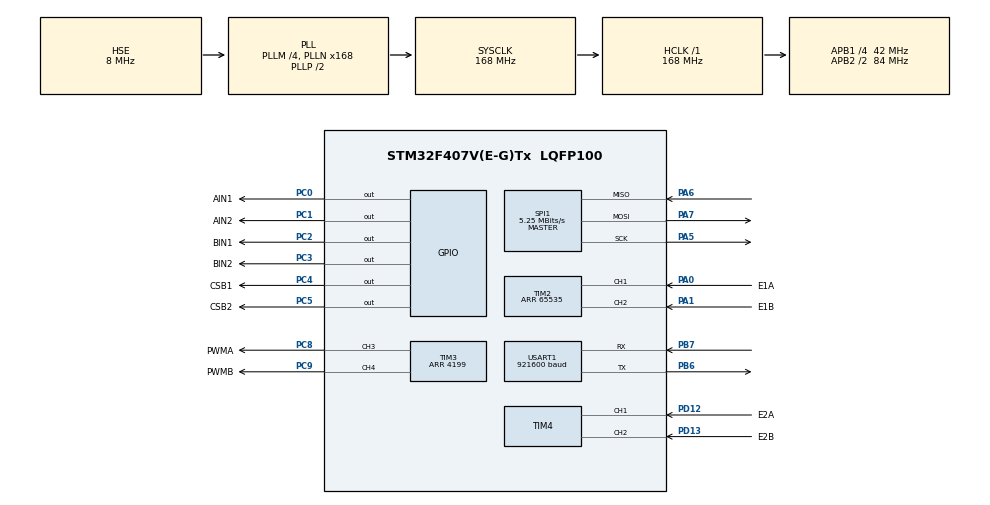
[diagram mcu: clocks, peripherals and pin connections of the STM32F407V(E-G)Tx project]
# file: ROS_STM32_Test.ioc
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Dma.Request0=SPI1_RX
Dma.Request1=SPI1_TX
Dma.Request2=USART1_RX
Dma.Request3=USART1_TX
Dma.SPI1_RX.0.Direction=DMA_PERIPH_TO_MEMORY
Dma.SPI1_RX.0.FIFOMode=DMA_FIFOMODE_DISABLE
Dma.SPI1_RX.0.Instance=DMA2_Stream0
Dma.SPI1_RX.0.MemDataAlignment=DMA_MDATAALIGN_BYTE
Dma.SPI1_RX.0.MemInc=DMA_MINC_ENABLE
Dma.SPI1_RX.0.Mode=DMA_NORMAL
Dma.SPI1_RX.0.PeriphDataAlignment=DMA_PDATAALIGN_BYTE
Dma.SPI1_RX.0.PeriphInc=DMA_PINC_DISABLE
Dma.SPI1_RX.0.Priority=DMA_PRIORITY_VERY_HIGH
Dma.SPI1_TX.1.Direction=DMA_MEMORY_TO_PERIPH
Dma.SPI1_TX.1.FIFOMode=DMA_FIFOMODE_DISABLE
Dma.SPI1_TX.1.Instance=DMA2_Stream3
Dma.SPI1_TX.1.MemDataAlignment=DMA_MDATAALIGN_BYTE
Dma.SPI1_TX.1.MemInc=DMA_MINC_ENABLE
Dma.SPI1_TX.1.Mode=DMA_NORMAL
Dma.SPI1_TX.1.PeriphDataAlignment=DMA_PDATAALIGN_BYTE
Dma.SPI1_TX.1.PeriphInc=DMA_PINC_DISABLE
Dma.SPI1_TX.1.Priority=DMA_PRIORITY_VERY_HIGH
Dma.USART1_RX.2.Direction=DMA_PERIPH_TO_MEMORY
Dma.USART1_RX.2.FIFOMode=DMA_FIFOMODE_DISABLE
Dma.USART1_RX.2.Instance=DMA2_Stream2
Dma.USART1_RX.2.MemDataAlignment=DMA_MDATAALIGN_BYTE
Dma.USART1_RX.2.MemInc=DMA_MINC_ENABLE
Dma.USART1_RX.2.Mode=DMA_CIRCULAR
Dma.USART1_RX.2.PeriphDataAlignment=DMA_PDATAALIGN_BYTE
Dma.USART1_RX.2.PeriphInc=DMA_PINC_DISABLE
Dma.USART1_RX.2.Priority=DMA_PRIORITY_HIGH
Dma.USART1_TX.3.Direction=DMA_MEMORY_TO_PERIPH
Dma.USART1_TX.3.FIFOMode=DMA_FIFOMODE_DISABLE
Dma.USART1_TX.3.Instance=DMA2_Stream7
Dma.USART1_TX.3.MemDataAlignment=DMA_MDATAALIGN_BYTE
Dma.USART1_TX.3.MemInc=DMA_MINC_ENABLE
Dma.USART1_TX.3.Mode=DMA_NORMAL
Dma.USART1_TX.3.PeriphDataAlignment=DMA_PDATAALIGN_BYTE
Dma.USART1_TX.3.PeriphInc=DMA_PINC_DISABLE
Dma.USART1_TX.3.Priority=DMA_PRIORITY_HIGH
Mcu.Family=STM32F4
Mcu.Name=STM32F407V(E-G)Tx
Mcu.Package=LQFP100
NVIC.DMA2_Stream0_IRQn=true\:0\:0\:false\:false\:true\:false\:true\:true
NVIC.DMA2_Stream2_IRQn=true\:0\:0\:false\:false\:true\:false\:true\:true
NVIC.DMA2_Stream3_IRQn=true\:0\:0\:false\:false\:true\:false\:true\:true
NVIC.DMA2_Stream7_IRQn=true\:0\:0\:false\:false\:true\:false\:true\:true
NVIC.PriorityGroup=NVIC_PRIORITYGROUP_4
NVIC.SPI1_IRQn=true\:0\:0\:false\:false\:true\:true\:true\:true
NVIC.TIM8_BRK_TIM12_IRQn=true\:2\:0\:true\:false\:true\:true\:true\:true
NVIC.USART1_IRQn=true\:1\:0\:true\:false\:true\:false\:true\:true
PA0-WKUP.GPIO_Label=E1A
PA0-WKUP.Signal=S_TIM2_CH1_ETR
PA1.GPIO_Label=E1B
PA1.Signal=S_TIM2_CH2
PA5.Mode=Full_Duplex_Master
PA5.Signal=SPI1_SCK
PA6.Mode=Full_Duplex_Master
PA6.Signal=SPI1_MISO
PA7.Mode=Full_Duplex_Master
PA7.Signal=SPI1_MOSI
PB6.Mode=Asynchronous
PB6.Signal=USART1_TX
PB7.Mode=Asynchronous
PB7.Signal=USART1_RX
PC0.GPIO_Label=AIN1
PC0.GPIO_Speed=GPIO_SPEED_FREQ_VERY_HIGH
PC0.PinState=GPIO_PIN_RESET
PC0.Signal=GPIO_Output
PC1.GPIO_Label=AIN2
PC1.GPIO_Speed=GPIO_SPEED_FREQ_VERY_HIGH
PC1.PinState=GPIO_PIN_RESET
PC1.Signal=GPIO_Output
PC2.GPIO_Label=BIN1
PC2.GPIO_Speed=GPIO_SPEED_FREQ_VERY_HIGH
PC2.PinState=GPIO_PIN_RESET
PC2.Signal=GPIO_Output
PC3.GPIO_Label=BIN2
PC3.GPIO_Speed=GPIO_SPEED_FREQ_VERY_HIGH
PC3.PinState=GPIO_PIN_RESET
PC3.Signal=GPIO_Output
PC4.GPIO_Label=CSB1
PC4.GPIO_Speed=GPIO_SPEED_FREQ_VERY_HIGH
PC4.PinState=GPIO_PIN_SET
PC4.Signal=GPIO_Output
PC5.GPIO_Label=CSB2
PC5.GPIO_Speed=GPIO_SPEED_FREQ_VERY_HIGH
PC5.PinState=GPIO_PIN_SET
PC5.Signal=GPIO_Output
PC8.GPIO_Label=PWMA
PC8.Signal=S_TIM3_CH3
PC9.GPIO_Label=PWMB
PC9.Signal=S_TIM3_CH4
PD12.GPIO_Label=E2A
PD12.Signal=S_TIM4_CH1
PD13.GPIO_Label=E2B
PD13.Signal=S_TIM4_CH2
PH0-OSC_IN.Mode=HSE-External-Oscillator
PH0-OSC_IN.Signal=RCC_OSC_IN
PH1-OSC_OUT.Mode=HSE-External-Oscillator
PH1-OSC_OUT.Signal=RCC_OSC_OUT
ProjectManager.HeapSize=0x200
ProjectManager.StackSize=0x400
ProjectManager.TargetToolchain=MDK-ARM V5.32
RCC.48MHZClocksFreq_Value=84000000
RCC.AHBFreq_Value=168000000
RCC.APB1CLKDivider=RCC_HCLK_DIV4
RCC.APB1Freq_Value=42000000
RCC.APB1TimFreq_Value=84000000
RCC.APB2CLKDivider=RCC_HCLK_DIV2
RCC.APB2Freq_Value=84000000
RCC.APB2TimFreq_Value=168000000
RCC.CortexFreq_Value=168000000
RCC.HCLKFreq_Value=168000000
RCC.HSE_VALUE=8000000
RCC.HSI_VALUE=16000000
RCC.LSE_VALUE=32768
RCC.PLLM=4
RCC.PLLN=168
RCC.PLLSourceVirtual=RCC_PLLSOURCE_HSE
RCC.SYSCLKFreq_VALUE=168000000
RCC.SYSCLKSource=RCC_SYSCLKSOURCE_PLLCLK
RCC.VCOOutputFreq_Value=336000000
SH.S_TIM2_CH1_ETR.0=TIM2_CH1,Encoder_Interface
SH.S_TIM2_CH2.0=TIM2_CH2,Encoder_Interface
SH.S_TIM3_CH3.0=TIM3_CH3,PWM Generation3 CH3
SH.S_TIM3_CH4.0=TIM3_CH4,PWM Generation4 CH4
SH.S_TIM4_CH1.0=TIM4_CH1,Encoder_Interface
SH.S_TIM4_CH2.0=TIM4_CH2,Encoder_Interface
SPI1.BaudRatePrescaler=SPI_BAUDRATEPRESCALER_16
SPI1.CalculateBaudRate=5.25 MBits/s
SPI1.Direction=SPI_DIRECTION_2LINES
SPI1.Mode=SPI_MODE_MASTER
SPI1.VirtualType=VM_MASTER
TIM12.Period=839
TIM12.Prescaler=99
TIM2.EncoderMode=TIM_ENCODERMODE_TI12
TIM2.Period=65535
TIM3.Channel-PWM\ Generation3\ CH3=TIM_CHANNEL_3
TIM3.Channel-PWM\ Generation4\ CH4=TIM_CHANNEL_4
TIM3.Period=4199
TIM4.EncoderMode=TIM_ENCODERMODE_TI12
USART1.BaudRate=921600
USART1.VirtualMode=VM_ASYNC
VP_TIM12_VS_ClockSourceINT.Mode=Internal
board=custom

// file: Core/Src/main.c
/* USER CODE BEGIN Header */
/**
  ******************************************************************************
  * @file           : main.c
  * @brief          : Main program body
  ******************************************************************************
  * @attention
  *
  * Copyright (c) 2026 STMicroelectronics.
  * All rights reserved.
  *
  * This software is licensed under terms that can be found in the LICENSE file
  * in the root directory of this software component.
  * If no LICENSE file comes with this software, it is provided AS-IS.
  *
  ******************************************************************************
  */
/* USER CODE END Header */
#include "main.h"

/* USER CODE BEGIN Includes */
#include "microros_app_includes.h"
/* USER CODE END Includes */

SPI_HandleTypeDef hspi1;
DMA_HandleTypeDef hdma_spi1_rx;
DMA_HandleTypeDef hdma_spi1_tx;

TIM_HandleTypeDef htim2;
TIM_HandleTypeDef htim3;
TIM_HandleTypeDef htim4;
TIM_HandleTypeDef htim12;

UART_HandleTypeDef huart1;
DMA_HandleTypeDef hdma_usart1_rx;
DMA_HandleTypeDef hdma_usart1_tx;

void SystemClock_Config(void);
static void MX_GPIO_Init(void);
static void MX_DMA_Init(void);
static void MX_SPI1_Init(void);
static void MX_TIM2_Init(void);
static void MX_TIM3_Init(void);
static void MX_TIM4_Init(void);
static void MX_USART1_UART_Init(void);
static void MX_TIM12_Init(void);

int main(void)
{

  /* MCU Configuration--------------------------------------------------------*/

  /* Reset of all peripherals, Initializes the Flash interface and the Systick. */
  HAL_Init();

  /* Configure the system clock */
  SystemClock_Config();

  /* Initialize all configured peripherals */
  MX_GPIO_Init();
  MX_DMA_Init();
  MX_SPI1_Init();
  MX_TIM2_Init();
  MX_TIM3_Init();
  MX_TIM4_Init();
  MX_USART1_UART_Init();
  MX_TIM12_Init();
  /* USER CODE BEGIN 2 */
  app_main_init();
  HAL_TIM_Base_Start_IT(&htim12);   /* 控制节拍中断，CubeMX 不会自动开 */
  /* USER CODE END 2 */

  /* Infinite loop */
  while (1)
  {

    /* USER CODE BEGIN 3 */
    app_loop();
  }
  /* USER CODE END 3 */
}

void SystemClock_Config(void)
{
  RCC_OscInitTypeDef RCC_OscInitStruct = {0};
  RCC_ClkInitTypeDef RCC_ClkInitStruct = {0};

  /** Configure the main internal regulator output voltage
  */
  __HAL_RCC_PWR_CLK_ENABLE();
  __HAL_PWR_VOLTAGESCALING_CONFIG(PWR_REGULATOR_VOLTAGE_SCALE1);

  /** Initializes the RCC Oscillators according to the specified parameters
  * in the RCC_OscInitTypeDef structure.
  */
  RCC_OscInitStruct.OscillatorType = RCC_OSCILLATORTYPE_HSE;
  RCC_OscInitStruct.HSEState = RCC_HSE_ON;
  RCC_OscInitStruct.PLL.PLLState = RCC_PLL_ON;
  RCC_OscInitStruct.PLL.PLLSource = RCC_PLLSOURCE_HSE;
  RCC_OscInitStruct.PLL.PLLM = 4;
  RCC_OscInitStruct.PLL.PLLN = 168;
  RCC_OscInitStruct.PLL.PLLP = RCC_PLLP_DIV2;
  RCC_OscInitStruct.PLL.PLLQ = 4;
  if (HAL_RCC_OscConfig(&RCC_OscInitStruct) != HAL_OK)
  {
    Error_Handler();
  }

  /** Initializes the CPU, AHB and APB buses clocks
  */
  RCC_ClkInitStruct.ClockType = RCC_CLOCKTYPE_HCLK|RCC_CLOCKTYPE_SYSCLK
                              |RCC_CLOCKTYPE_PCLK1|RCC_CLOCKTYPE_PCLK2;
  RCC_ClkInitStruct.SYSCLKSource = RCC_SYSCLKSOURCE_PLLCLK;
  RCC_ClkInitStruct.AHBCLKDivider = RCC_SYSCLK_DIV1;
  RCC_ClkInitStruct.APB1CLKDivider = RCC_HCLK_DIV4;
  RCC_ClkInitStruct.APB2CLKDivider = RCC_HCLK_DIV2;

  if (HAL_RCC_ClockConfig(&RCC_ClkInitStruct, FLASH_LATENCY_5) != HAL_OK)
  {
    Error_Handler();
  }
}

static void MX_SPI1_Init(void)
{

  /* SPI1 parameter configuration*/
  hspi1.Instance = SPI1;
  hspi1.Init.Mode = SPI_MODE_MASTER;
  hspi1.Init.Direction = SPI_DIRECTION_2LINES;
  hspi1.Init.DataSize = SPI_DATASIZE_8BIT;
  hspi1.Init.CLKPolarity = SPI_POLARITY_LOW;
  hspi1.Init.CLKPhase = SPI_PHASE_1EDGE;
  hspi1.Init.NSS = SPI_NSS_SOFT;
  hspi1.Init.BaudRatePrescaler = SPI_BAUDRATEPRESCALER_16;
  hspi1.Init.FirstBit = SPI_FIRSTBIT_MSB;
  hspi1.Init.TIMode = SPI_TIMODE_DISABLE;
  hspi1.Init.CRCCalculation = SPI_CRCCALCULATION_DISABLE;
  hspi1.Init.CRCPolynomial = 10;
  if (HAL_SPI_Init(&hspi1) != HAL_OK)
  {
    Error_Handler();
  }

}

static void MX_TIM2_Init(void)
{

  TIM_Encoder_InitTypeDef sConfig = {0};
  TIM_MasterConfigTypeDef sMasterConfig = {0};

  htim2.Instance = TIM2;
  htim2.Init.Prescaler = 0;
  htim2.Init.CounterMode = TIM_COUNTERMODE_UP;
  htim2.Init.Period = 65535;
  htim2.Init.ClockDivision = TIM_CLOCKDIVISION_DIV1;
  htim2.Init.AutoReloadPreload = TIM_AUTORELOAD_PRELOAD_DISABLE;
  sConfig.EncoderMode = TIM_ENCODERMODE_TI12;
  sConfig.IC1Polarity = TIM_ICPOLARITY_RISING;
  sConfig.IC1Selection = TIM_ICSELECTION_DIRECTTI;
  sConfig.IC1Prescaler = TIM_ICPSC_DIV1;
  sConfig.IC1Filter = 0;
  sConfig.IC2Polarity = TIM_ICPOLARITY_RISING;
  sConfig.IC2Selection = TIM_ICSELECTION_DIRECTTI;
  sConfig.IC2Prescaler = TIM_ICPSC_DIV1;
  sConfig.IC2Filter = 0;
  if (HAL_TIM_Encoder_Init(&htim2, &sConfig) != HAL_OK)
  {
    Error_Handler();
  }
  sMasterConfig.MasterOutputTrigger = TIM_TRGO_RESET;
  sMasterConfig.MasterSlaveMode = TIM_MASTERSLAVEMODE_DISABLE;
  if (HAL_TIMEx_MasterConfigSynchronization(&htim2, &sMasterConfig) != HAL_OK)
  {
    Error_Handler();
  }

}

static void MX_TIM3_Init(void)
{

  TIM_MasterConfigTypeDef sMasterConfig = {0};
  TIM_OC_InitTypeDef sConfigOC = {0};

  htim3.Instance = TIM3;
  htim3.Init.Prescaler = 0;
  htim3.Init.CounterMode = TIM_COUNTERMODE_UP;
  htim3.Init.Period = 4199;
  htim3.Init.ClockDivision = TIM_CLOCKDIVISION_DIV1;
  htim3.Init.AutoReloadPreload = TIM_AUTORELOAD_PRELOAD_DISABLE;
  if (HAL_TIM_PWM_Init(&htim3) != HAL_OK)
  {
    Error_Handler();
  }
  sMasterConfig.MasterOutputTrigger = TIM_TRGO_RESET;
  sMasterConfig.MasterSlaveMode = TIM_MASTERSLAVEMODE_DISABLE;
  if (HAL_TIMEx_MasterConfigSynchronization(&htim3, &sMasterConfig) != HAL_OK)
  {
    Error_Handler();
  }
  sConfigOC.OCMode = TIM_OCMODE_PWM1;
  sConfigOC.Pulse = 0;
  sConfigOC.OCPolarity = TIM_OCPOLARITY_HIGH;
  sConfigOC.OCFastMode = TIM_OCFAST_DISABLE;
  if (HAL_TIM_PWM_ConfigChannel(&htim3, &sConfigOC, TIM_CHANNEL_3) != HAL_OK)
  {
    Error_Handler();
  }
  if (HAL_TIM_PWM_ConfigChannel(&htim3, &sConfigOC, TIM_CHANNEL_4) != HAL_OK)
  {
    Error_Handler();
  }
  HAL_TIM_MspPostInit(&htim3);

}

static void MX_TIM4_Init(void)
{

  TIM_Encoder_InitTypeDef sConfig = {0};
  TIM_MasterConfigTypeDef sMasterConfig = {0};

  htim4.Instance = TIM4;
  htim4.Init.Prescaler = 0;
  htim4.Init.CounterMode = TIM_COUNTERMODE_UP;
  htim4.Init.Period = 65535;
  htim4.Init.ClockDivision = TIM_CLOCKDIVISION_DIV1;
  htim4.Init.AutoReloadPreload = TIM_AUTORELOAD_PRELOAD_DISABLE;
  sConfig.EncoderMode = TIM_ENCODERMODE_TI12;
  sConfig.IC1Polarity = TIM_ICPOLARITY_RISING;
  sConfig.IC1Selection = TIM_ICSELECTION_DIRECTTI;
  sConfig.IC1Prescaler = TIM_ICPSC_DIV1;
  sConfig.IC1Filter = 0;
  sConfig.IC2Polarity = TIM_ICPOLARITY_RISING;
  sConfig.IC2Selection = TIM_ICSELECTION_DIRECTTI;
  sConfig.IC2Prescaler = TIM_ICPSC_DIV1;
  sConfig.IC2Filter = 0;
  if (HAL_TIM_Encoder_Init(&htim4, &sConfig) != HAL_OK)
  {
    Error_Handler();
  }
  sMasterConfig.MasterOutputTrigger = TIM_TRGO_RESET;
  sMasterConfig.MasterSlaveMode = TIM_MASTERSLAVEMODE_DISABLE;
  if (HAL_TIMEx_MasterConfigSynchronization(&htim4, &sMasterConfig) != HAL_OK)
  {
    Error_Handler();
  }

}

static void MX_TIM12_Init(void)
{

  TIM_ClockConfigTypeDef sClockSourceConfig = {0};

  htim12.Instance = TIM12;
  htim12.Init.Prescaler = 99;
  htim12.Init.CounterMode = TIM_COUNTERMODE_UP;
  htim12.Init.Period = 839;
  htim12.Init.ClockDivision = TIM_CLOCKDIVISION_DIV1;
  htim12.Init.AutoReloadPreload = TIM_AUTORELOAD_PRELOAD_DISABLE;
  if (HAL_TIM_Base_Init(&htim12) != HAL_OK)
  {
    Error_Handler();
  }
  sClockSourceConfig.ClockSource = TIM_CLOCKSOURCE_INTERNAL;
  if (HAL_TIM_ConfigClockSource(&htim12, &sClockSourceConfig) != HAL_OK)
  {
    Error_Handler();
  }

}

static void MX_USART1_UART_Init(void)
{

  huart1.Instance = USART1;
  huart1.Init.BaudRate = 921600;
  huart1.Init.WordLength = UART_WORDLENGTH_8B;
  huart1.Init.StopBits = UART_STOPBITS_1;
  huart1.Init.Parity = UART_PARITY_NONE;
  huart1.Init.Mode = UART_MODE_TX_RX;
  huart1.Init.HwFlowCtl = UART_HWCONTROL_NONE;
  huart1.Init.OverSampling = UART_OVERSAMPLING_16;
  if (HAL_UART_Init(&huart1) != HAL_OK)
  {
    Error_Handler();
  }

}

static void MX_DMA_Init(void)
{

  /* DMA controller clock enable */
  __HAL_RCC_DMA2_CLK_ENABLE();

  /* DMA interrupt init */
  /* DMA2_Stream0_IRQn interrupt configuration */
  HAL_NVIC_SetPriority(DMA2_Stream0_IRQn, 0, 0);
  HAL_NVIC_EnableIRQ(DMA2_Stream0_IRQn);
  /* DMA2_Stream2_IRQn interrupt configuration */
  HAL_NVIC_SetPriority(DMA2_Stream2_IRQn, 0, 0);
  HAL_NVIC_EnableIRQ(DMA2_Stream2_IRQn);
  /* DMA2_Stream3_IRQn interrupt configuration */
  HAL_NVIC_SetPriority(DMA2_Stream3_IRQn, 0, 0);
  HAL_NVIC_EnableIRQ(DMA2_Stream3_IRQn);
  /* DMA2_Stream7_IRQn interrupt configuration */
  HAL_NVIC_SetPriority(DMA2_Stream7_IRQn, 0, 0);
  HAL_NVIC_EnableIRQ(DMA2_Stream7_IRQn);

}

static void MX_GPIO_Init(void)
{
  GPIO_InitTypeDef GPIO_InitStruct = {0};

  /* GPIO Ports Clock Enable */
  __HAL_RCC_GPIOH_CLK_ENABLE();
  __HAL_RCC_GPIOC_CLK_ENABLE();
  __HAL_RCC_GPIOA_CLK_ENABLE();
  __HAL_RCC_GPIOD_CLK_ENABLE();
  __HAL_RCC_GPIOB_CLK_ENABLE();

  /*Configure GPIO pin Output Level */
  HAL_GPIO_WritePin(GPIOC, AIN1_Pin|AIN2_Pin|BIN1_Pin|BIN2_Pin, GPIO_PIN_RESET);

  /*Configure GPIO pin Output Level */
  HAL_GPIO_WritePin(GPIOC, CSB1_Pin|CSB2_Pin, GPIO_PIN_SET);

  /*Configure GPIO pins : AIN1_Pin AIN2_Pin BIN1_Pin BIN2_Pin
                           CSB1_Pin CSB2_Pin */
  GPIO_InitStruct.Pin = AIN1_Pin|AIN2_Pin|BIN1_Pin|BIN2_Pin
                          |CSB1_Pin|CSB2_Pin;
  GPIO_InitStruct.Mode = GPIO_MODE_OUTPUT_PP;
  GPIO_InitStruct.Pull = GPIO_NOPULL;
  GPIO_InitStruct.Speed = GPIO_SPEED_FREQ_VERY_HIGH;
  HAL_GPIO_Init(GPIOC, &GPIO_InitStruct);

}

void Error_Handler(void)
{
  __disable_irq();
  while (1)
  {
  }
}
